# M5531 register map
File version: 1.0
Registers are 32-bit, read-write, reset 0x0 unless marked. A register's access mark holds for its fields unless they carry their own. Offsets are from the block's base; [hi:lo] are bit positions; 'fields as' and 'values as' point back to an identical list.

## GDMA (part 2 of 2) — GDMA Register Map
Base 0x04004000
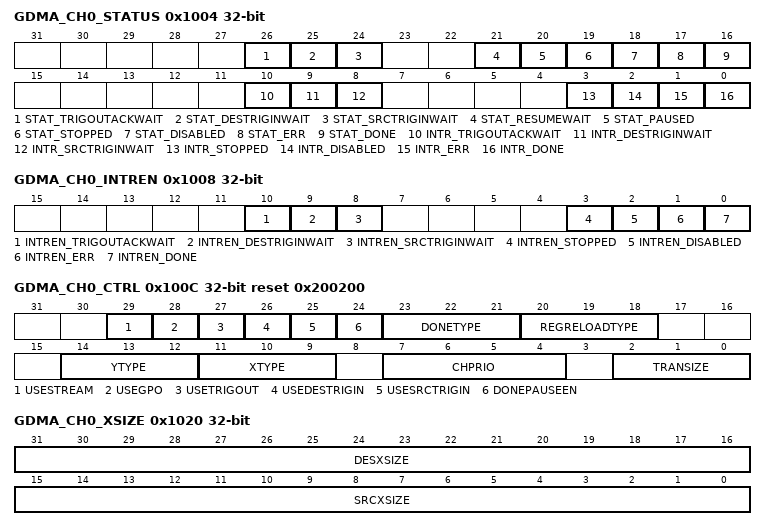
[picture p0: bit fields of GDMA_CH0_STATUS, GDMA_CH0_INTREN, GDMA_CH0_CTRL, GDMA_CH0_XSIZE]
0x1004 GDMA_CH0_STATUS — GDMA Channel Status Register
  [26] STAT_TRIGOUTACKWAIT — Channel is waiting for output Trigger Acknowledgement Status
    0=The output trigger acknowledgement is received either from HW or SW source; 1=DMA channel starts waiting for output trigger acknowledgement
  [25] STAT_DESTRIGINWAIT — Channel is waiting for Destination Trigger Status
    0=The destination trigger request is received either from HW or SW source; 1=DMA channel starts waiting for destination input trigger request
  [24] STAT_SRCTRIGINWAIT — Channel is waiting for Source Trigger Status
    0=The source trigger request is received either from HW or SW source; 1=DMA channel starts waiting for source input trigger request
  [21] STAT_RESUMEWAIT — Waiting for resume from software Flag. This flag indicates that the DMA channel successfully paused the operation of the command and needs SW acknowledgment to resume the operation.
    0=The RESUMECMD bit is set in the command register; 1=If STAT_PAUSED is asserted and the PAUSECMD bit set in the command register or when the STAT_DONE is asserted and the DONEPAUSEEN bit is set
  [20] STAT_PAUSED — Paused Status Flag
    0=When the request to pause is not asserted anymore and the command operation can continue; 1=The DMA channel successfully paused the operation of the command. The pause request can come from many internal or external sources
  [19] STAT_STOPPED — Stopped Status Flag
    0=Automatically cleared when the ENABLECMD is set; 1=The DMA channel successfully reached the stopped state. The stop request can come from many internal or external sources. Write '1' to this bit to clear it
  [18] STAT_DISABLED — Disabled Status Flag
    0=Automatically cleared when the ENABLECMD is set; 1=The DMA channel is successfully disabled using the DISABLECMD command. Write '1' to this bit to clear it
  [17] STAT_ERR — Error Status Flag. Write '1' to this bit to clear it. When cleared, it also clears the ERRINFO register.
    0=Automatically cleared when the ENABLECMD is set; 1=The DMA encounters an error during its operation. The details about the error event can be found in the ERRINFO register
  [16] STAT_DONE — Done Status Flag
    0=Automatically cleared when the ENABLECMD is set; 1=The DMA command reaches the state defined by the DONETYPE settings. When DONEPAUSEEN is set the DMA command operation is paused when this flag is asserted. Write '1' to this bit to clear it
  [10] INTR_TRIGOUTACKWAIT — Channel is waiting for output Trigger Acknowledgement Interrupt Flag
    0=Automatically cleared when STAT_TRIGOUTACKWAIT is cleared; 1=The INTREN_TRIGOUTACKWAIT is set and the STAT_TRIGOUTACKWAIT status flag is asserted
  [9] INTR_DESTRIGINWAIT — Channel is waiting for Destination Trigger Interrupt Flag
    0=Automatically cleared when STAT_DESTRIGINWAIT is cleared; 1=The INTREN_DESTRIGINWAIT is set and the STAT_DESTRIGINWAIT status flag is asserted
  [8] INTR_SRCTRIGINWAIT — Channel is waiting for Source Trigger Interrupt Flag
    0=Automatically cleared when STAT_SRCTRIGINWAIT is cleared; 1=The INTREN_SRCTRIGINWAIT is set and the STAT_SRCTRIGINWAIT status flag is asserted
  [3] INTR_STOPPED — Stopped Interrupt Flag
    0=Automatically cleared when STAT_STOPPED is cleared; 1=The INTREN_STOPPED is set and the STAT_STOPPED flag gets raised. 0
  [2] INTR_DISABLED — Disabled Interrupt Flag
    0=Automatically cleared when STAT_DISABLED is cleared; 1=The INTREN_DISABLED is set and the STAT_DISABLED flag gets raised
  [1] INTR_ERR — Error Interrupt Flag
    0=Automatically cleared when STAT_ERR is cleared; 1=The INTREN_ERR is set and the STAT_ERR status flag gets raised
  [0] INTR_DONE — Done Interrupt Flag
    0=Automatically cleared when STAT_DONE is cleared; 1=The INTREN_DONE is set and the STAT_DONE status flag gets raised
0x1008 GDMA_CH0_INTREN — GDMA Channel Interrupt Enable Register
  [10] INTREN_TRIGOUTACKWAIT — Channel is waiting for output Trigger Acknowledgement Interrupt Enable
    0=It prevents INTR_TRIGOUTACKWAIT to be asserted. Currently pending interrupts are not affected by clearing this bit; 1=Enables INTR_TRIGOUTACKWAIT to be set and raise an interrupt when STAT_TRIGOUTACKWAIT status flag is asserted
  [9] INTREN_DESTRIGINWAIT — Channel is waiting for destination Trigger Interrupt Enable
    0=It prevents INTR_DESTRIGINWAIT to be asserted. Currently pending interrupts are not affected by clearing this bit; 1=Enables INTR_DESTRIGINWAIT to be set and raise an interrupt when STAT_DESTRIGINWAIT status flag is asserted
  [8] INTREN_SRCTRIGINWAIT — Channel is waiting for Source Trigger Interrupt Enable
    0=It prevents INTR_SRCTRIGINWAIT to be asserted. Currently pending interrupts are not affected by clearing this bit; 1=Enables INTR_SRCTRIGINWAIT to be set and raise an interrupt when STAT_SRCTRIGINWAIT status flag is asserted
  [3] INTREN_STOPPED — Stopped Interrupt Enable
    0=It prevents INTR_STOPPED to be asserted. Currently pending interrupts are not affected by clearing this bit; 1=Enables INTR_STOPPED to be set and raise an interrupt when STAT_STOPPED status flag is asserted
  [2] INTREN_DISABLED — Disabled Interrupt Enable
    0=It prevents INTR_DISABLED to be asserted. Currently pending interrupts are not affected by clearing this bit; 1=Enables INTR_DISABLED to be set and raise an interrupt when STAT_DISABLED status flag is asserted
  [1] INTREN_ERR — Error Interrupt Enable
    0=It prevents INTR_ERR to be asserted. Currently pending interrupts are not affected by clearing this bit; 1=Enables INTR_ERROR to be set and raise an interrupt when the STAT_ERR status flag is asserted
  [0] INTREN_DONE — Done Interrupt Enable
    0=It prevents INTR_DONE to be asserted. Currently pending interrupts are not affected by clearing this bit; 1=Enables the INTR_DONE to be set and raise an interrupt when the STAT_DONE status flag is asserted
0x100C GDMA_CH0_CTRL reset 0x200200 — GDMA Channel Control Register
  [29] USESTREAM — Enable Stream Interface use for this command
    0=Disable; 1=Enable the field is RAZ/WI when the following condition is False: CH_STREAM_EN
  [28] USEGPO — Enable GPO use for this command (CH_GPO_EN * GPO_WIDTH) 0
    0=Disable; 1=Enable the field is RAZ/WI when the following condition is False:
  [27] USETRIGOUT — Enable Trigger Output use for this command
    0=Disable; 1=Enable
  [26] USEDESTRIGIN — Enable Destination Trigger Input use for this command
    0=Disable; 1=Enable
  [25] USESRCTRIGIN — Enable Source Trigger Input use for this command
    0=Disable; 1=Enable
  [24] DONEPAUSEEN — Done pause enable
    0=The assertion of the STAT_DONE does not pause the progress of the command and the next operation of the channel will be started immediately after the STAT_DONE flag is set; 1=The assertion of the STAT_DONE flag results in an automatic pause request for the current DMA operation. When the paused state is reached the STAT_RESUMEWAIT flag is also set
  [23:21] DONETYPE — Done type selection. This field defines when the STAT_DONE status flag is asserted during the command operation.
    0=STAT_DONE flag is not asserted for this command; 1=End of a command, before jumping to the next linked command. (default); 3=End of an autorestart cycle, before starting the next cycle
  [20:18] REGRELOADTYPE — Automatic register reload type. Defines how the DMA command reloads initial values at the end of a DMA command before autorestarting, ending or linking to a new DMA command: - 000: Reload Disabled. Note: When CLEARCMD is set, the reloaded registers will also be cleared
    1=Reload source and destination size registers only; 3=Reload source address only and all source and destination size registers; 5=Reload destination address only and all source and destination size registers; 7=Reload source and destination address and all source and destination size registers
  [14:12] YTYPE — Operation type for Y direction. Note: The field is RAZ/WI when the following condition is False: CH_EXT_FEAT_EN
    0='disable' - Only do 1D transfers. When HAS_2D is 0, meaning 2D capability is not supported in HW, the YTYPE is always '000'; 1='continue' - Copy 2D data in a continuous manner from source area to the destination area by using the YSIZE registers. The copy stops when the source runs out of data or the destination runs out of space. Not supported when HAS_2D is 0 in HW; 2='wrap' - Wrap the 2D source area within the destination 2D area by starting to copy data from the beginning of the first source line to the remaining space in the destination area. If the destination area is smaller than the source area then the behavior is UNPREDICTABLE. Not supported when HAS_WRAP or HAS_2D is 0 in HW; 3=Fill the remainder of the destination area with FILLVAL when the source area runs out of data. If the destination area is smaller than the source area then the behavior is UNPREDICTABLE. Not supported when HAS_WRAP or HAS_2D is 0 in HW
  [11:9] XTYPE — Operation type for X direction
    0='disable' - No data transfer will take place for this command. This mode can be used to create empty commands that wait for an event or set GPOs; 1='continue' - Copy data in a continuous manner from source to the destination; 2='wrap' - Wrap source data within a destination line when the end of the source line is reached. Read starts again from the beginning of the source line and copied to the remainder of the destination line; 3='fill' - Fill the remainder of the destination line with FILLVAL when the end of the source line is reached. If the DESXSIZE is smaller than SRCXSIZE then the behavior is UNPREDICTABLE. Not supported when HAS_WRAP is 0 in HW
  [7:4] CHPRIO — Channel Priority
    0=Lowest Priority; 15=Highest Priority
  [2:0] TRANSIZE — Transfer Entity Size. Note that DATA_WIDTH limits this field. Address will be aligned to TRANSIZE by the DMAC by ignoring the lower bits.
    0=Byte; 1=Halfworld; 2=Word; 3=Doubleword; 4=128-bits; 5=256-bits; 6=512-bits; 7=1024-bits
0x1010 GDMA_CH0_SRCADDR — GDMA Channel Source Address Register
  [31:0] SRCADDR — Source Address[31:0]
0x1018 GDMA_CH0_DESADDR — GDMA Channel Destination Address Register
  [31:0] DESADDR — Destination Address[31:0]
0x1020 GDMA_CH0_XSIZE — GDMA Channel X Dimension Size Register, Lower Bits [15:0]
  [31:16] DESXSIZE — Destination Number of Transfers in the X Dimension lower bits [15:0]. This register along with DESXSIZEHI defines the destination data block size of the DMA operation for or any 1D operation, and defines the X dimension of the 2D destination block for a 2D operation. HAS_WRAP or HAS_STREAM configuration needs to be set to allow writes to this register, otherwise it is read-only and writing to SRCXSIZE will also update the value of this register
  [15:0] SRCXSIZE — Source Number of Transfers in the X Dimension lower bits [15:0]. This register along with SRCXSIZEHI defines the source data block size of the DMA operation for any 1D operation, and defines the X dimension of the 2D source block for 2D operation.
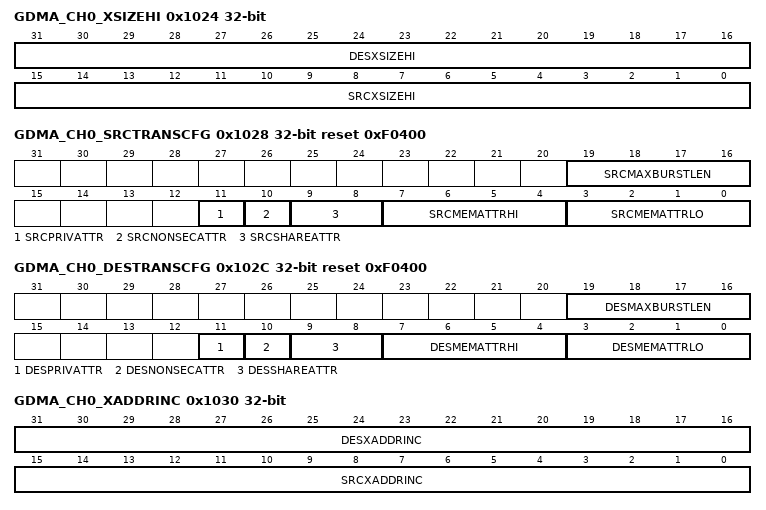
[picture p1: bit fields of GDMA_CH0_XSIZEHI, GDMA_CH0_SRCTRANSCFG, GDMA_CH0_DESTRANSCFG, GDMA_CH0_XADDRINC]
0x1024 GDMA_CH0_XSIZEHI — GDMA Channel X Dimension Size Register, High Bits [31:16]
  [31:16] DESXSIZEHI — Destination Number of Transfers in the X Dimension high bits [31:16]. This register along with DESXSIZE defines the destination data block size of the DMA operation for or any 1D operation, and defines the X dimension of the 2D destination block for a 2D operation. HAS_WRAP or HAS_STREAM configuration needs to be set to allow writes to this register, otherwise it is readonly and writing to SRCXSIZEHI will also update the value of this register.
  [15:0] SRCXSIZEHI — Source Number of Transfers in the X Dimension high bits [31:16]. This register along with SRCXSIZE defines the source data block size of the DMA operation for any 1D operation, and defines the X dimension of the 2D source block for 2D operation.
0x1028 GDMA_CH0_SRCTRANSCFG reset 0xF0400 — GDMA Channel Source Transfer Configuration Register
  [19:16] SRCMAXBURSTLEN — Source Max Burst Length. Hint for the DMA on what is the maximum allowed burst size it can use for read transfers. The maximum number of beats sent by the DMA for a read burst is equal to SRCMAXBURSTLEN + 1. Default value is 16 beats, which allows the DMA to set all burst sizes. Note: Limited by the DATA_BUFF_SIZE so larger settings may not always result in larger bursts.
  [11] SRCPRIVATTR — Source Transfer Privilege Attribute
    0=Unprivileged; 1=Privileged When a channel is unprivileged this bit is tied to 0
  [10] SRCNONSECATTR — Source Transfer Non-secure Attribute
    0=Secure; 1=Non-secure When a channel is Non-secure this bit is tied to 1
  [9:8] SRCSHAREATTR — SRCSHAREATTR Source Transfer Shareability Attribute
    0=Non-shareable; 2=Outer shareable; 3=Inner shareable
  [7:4] SRCMEMATTRHI — Source Transfer Memory Attribute field [7:4]
    0=Device memory; 1=Normal memory, Outer Write allocate, Outer Write-through transient; 2=Normal memory, Outer Read allocate, Outer Write-through transient; 3=Normal memory, Outer Read/Write allocate, Outer Write-through transient; 4=Normal memory, Outer non-cacheable; 5=Normal memory, Outer Write allocate, Outer Write-back transient; 6=Normal memory, Outer Read allocate, Outer Write-back transient; 7=Normal memory, Outer Read/Write allocate, Outer Write-back transient; 8=Normal memory, Outer Write-through non-transient; 9=Normal memory, Outer Write allocate, Outer Write-through non-transient; 10=Normal memory, Outer Read allocate, Outer Write-through non-transient; 11=Normal memory, Outer Read/Write allocate, Outer Write-through non-transient; 12=Normal memory, Outer Write-back non-transient; 13=Normal memory, Outer Write allocate, Outer Write-back non-transient; 14=Normal memory, Outer Read allocate, Outer Write-back non-transient; 15=Normal memory, Outer Read/Write allocate, Outer Write-back non-transient
  [3:0] SRCMEMATTRLO — Source Transfer Memory Attribute field [3:0]. When SRCMEMATTRHI is Device type (0000) then this field means:
    0=Device-nGnRnE. Reserved; 1=Normal memory, Inner Write allocate, Inner Write-through transient; 2=Normal memory, Inner Read allocate, Inner Write-through transient; 3=Normal memory, Inner Read/Write allocate, Inner Write-through transient; 4=Device-nGnRE. Normal memory, Inner non-cacheable; 5=Normal memory, Inner Write allocate, Inner Write-back transient; 6=Normal memory, Inner Read allocate, Inner Write-back transient; 7=Normal memory, Inner Read/Write allocate, Inner Write-back transient; 8=Device-nGRE. Normal memory, Inner Write-through non-transient; 9=Normal memory, Inner Write allocate, Inner Write-through non-transient; 10=Normal memory, Inner Read allocate, Inner Write-through non-transient; 11=Normal memory, Inner Read/Write allocate, Inner Write-through non-transient; 12=Device-GRE. Normal memory, Inner Write-back non-transient; 13=Normal memory, Inner Write allocate, Inner Write-back non-transient; 14=Normal memory, Inner Read allocate, Inner Write-back non-transient; 15=Normal memory, Inner Read/Write allocate, Inner Write-back non-transient
0x102C GDMA_CH0_DESTRANSCFG reset 0xF0400 — GDMA Channel Destination Transfer Configuration Register
  [19:16] DESMAXBURSTLEN — Destination Max Burst Length. Hint for the DMA on what is the maximum allowed burst size it can use for write transfers. The maximum number of beats sent by the DMA for a write burst is equal to DESMAXBURSTLEN + 1. Default value is 16 beats, which allows the DMA to set all burst sizes. Note: Limited by the DATA_BUFF_SIZE so larger settings may not always result in larger bursts.
  [11] DESPRIVATTR — Destination Transfer Privilege Attribute
    values as GDMA_CH0_SRCTRANSCFG.SRCPRIVATTR
  [10] DESNONSECATTR — Destination Transfer Non-secure Attribute
    values as GDMA_CH0_SRCTRANSCFG.SRCNONSECATTR
  [9:8] DESSHAREATTR — Destination Transfer Shareability Attribute
    0=Non-shareable; 2=Outer shareable; 3=Inner shareable
  [7:4] DESMEMATTRHI — Destination Transfer Memory Attribute field [7:4]
    values as GDMA_CH0_SRCTRANSCFG.SRCMEMATTRHI
  [3:0] DESMEMATTRLO — Destination Transfer Memory Attribute field [3:0]. When DESMEMATTRHI is Device type (0000) then this field means:
    values as GDMA_CH0_SRCTRANSCFG.SRCMEMATTRLO
0x1030 GDMA_CH0_XADDRINC — GDMA Channel X Dimension Address Increment Register
  [31:16] DESXADDRINC — Destination X dimension Address Increment
  [15:0] SRCXADDRINC — Source X dimension Address Increment
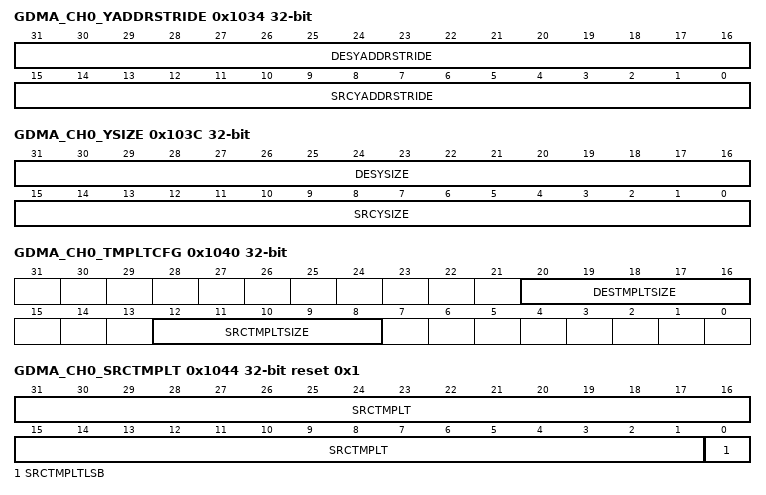
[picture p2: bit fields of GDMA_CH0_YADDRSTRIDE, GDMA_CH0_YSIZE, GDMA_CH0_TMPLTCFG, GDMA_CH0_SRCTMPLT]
0x1034 GDMA_CH0_YADDRSTRIDE — GDMA Channel Y Dimension Address Stride Register
  [31:16] DESYADDRSTRIDE — Destination Address Stride between lines
  [15:0] SRCYADDRSTRIDE — Source Address Stride between lines
0x1038 GDMA_CH0_FILLVAL — GDMA Channel Fill Pattern Value Register
  [31:0] FILLVAL — Fill pattern value. When XTYPE or YTYPE is set to fill mode, then this register value is used on the write data bus when the command starts to fill the memory area. The TRANSIZE defines the width of the FILLVAL used for the command. For byte transfers the FILLVAL[7:0] is used, other bits are ignored. For halfword transfers the FILLVAL[15:0] is used, other bits are ignored. For 64-bit and wider transfers the FILLVAL[31:0] pattern is repeated on the full width of the data bus. Not present when HAS_WRAP is 0. The field is RAZ/WI when the following condition is False: CH_EXT_FEAT_EN
0x103C GDMA_CH0_YSIZE — GDMA Channel Y Dimensions Size Register
  [31:16] DESYSIZE — Destination Y dimension or number of lines. Not present when HAS_2D is 0. HAS_WRAP or HAS_STREAM configuration needs to be set to allow writes to this register, otherwise it is read-only. The field is RAZ/WI when the following condition is False: CH_EXT_FEAT_EN
  [15:0] SRCYSIZE — Source Y dimension or number of lines. Not present when HAS_2D is 0. The field is RAZ/WI when the following condition is False: CH_EXT_FEAT_EN
0x1040 GDMA_CH0_TMPLTCFG — GDMA Channel Template Configuration Register
  [20:16] DESTMPLTSIZE — Destination Template Size in number of transfers plus one
    0=Destination template is disabled
  [12:8] SRCTMPLTSIZE — Source Template Size in number of transfers plus one
    0=Source template is disabled
0x1044 GDMA_CH0_SRCTMPLT reset 0x1 — GDMA Channel 0 Source Template Pattern Register
  [31:1] SRCTMPLT — Source Packing Template. Bit[0] is read only and always set to 1 as template patterns can only start from the base address of the transfer. Not present when HAS_TMPLT is 0. The field is RAZ/WI when the following condition is False: CH_EXT_FEAT_EN
  [0] SRCTMPLTLSB — Source Packing Template Least Significant Bit. This bit of the template is read only and always set to 1 as template patterns can only start from the base address of the transfer. Not present when HAS_TMPLT is 0. The field is RAZ/WI when the following condition is False: CH_EXT_FEAT_EN
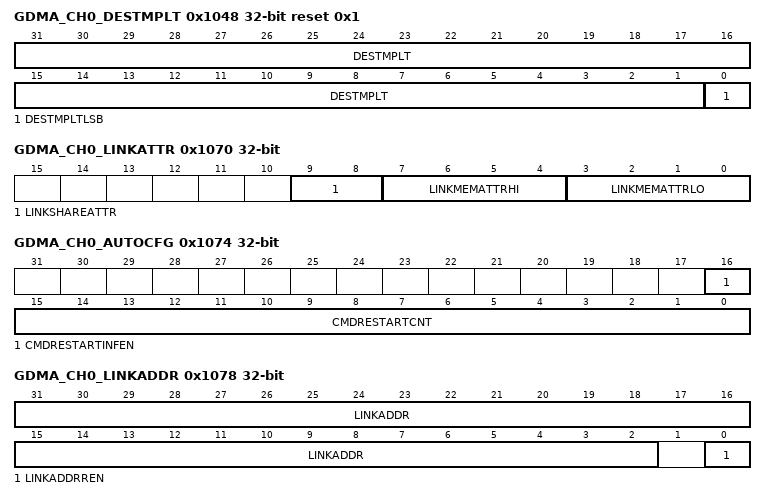
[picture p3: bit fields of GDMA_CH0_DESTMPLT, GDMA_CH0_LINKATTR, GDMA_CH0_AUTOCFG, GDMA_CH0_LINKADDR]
0x1048 GDMA_CH0_DESTMPLT reset 0x1 — GDMA Channel 0 Destination Template Pattern Register
  [31:1] DESTMPLT — Destination Packing Template. Bit[0] is read only and always set to 1 as template patterns can only start from the base address of the transfer. Not present when HAS_TMPLT is 0. The field is RAZ/WI when the following condition is False: CH_EXT_FEAT_EN
  [0] DESTMPLTLSB — Destination Packing Template Least Significant Bit. This bit of the template is read only and always set to 1 as template patterns can only start from the base address of the transfer. Not present when HAS_TMPLT is 0. The field is RAZ/WI when the following condition is False: CH_EXT_FEAT_EN
0x1070 GDMA_CH0_LINKATTR — GDMA Channel Link Address Memory Attributes Register
  [9:8] LINKSHAREATTR — Link Address Transfer Shareability Attribute
    0=Non-shareable; 2=Outer shareable; 3=Inner shareable
  [7:4] LINKMEMATTRHI — Link Address Read Transfer Memory Attribute field [7:4]
    0=Device memory; 1=Normal memory, Outer Write allocate, Outer Write-through transient; 2=Normal memory, Outer Read allocate, Outer Write-through transient; 3=Normal memory, Outer Read/Write allocate, Outer Write-through transient; 4=Normal memory, Outer non-cacheable; 5=Normal memory, Outer Write allocate, Outer Write-back transient; 6=Normal memory, Outer Read allocate, Outer Write-back transient; 7=Normal memory, Outer Read/Write allocate, Outer Write-back transient; 8=Normal memory, Outer Write-through non-transient; 9=Normal memory, Outer Write allocate, Outer Write-through non-transient; 10=Normal memory, Outer Read allocate, Outer Write-through non-transient; 11=Normal memory, Outer Read/Write allocate, Outer Write-through non-transient; 12=Normal memory, Outer Write-back non-transient; 13=Normal memory, Outer Write allocate, Outer Write-back non-transient; 14=Normal memory, Outer Read allocate, Outer Write-back non-transient; 15=Normal memory, Outer Read/Write allocate, Outer Write-back non-transien
  [3:0] LINKMEMATTRLO — Link Address Read Transfer Memory Attribute field [3:0]. When LINKMEMATTRHI is Device type (0000) then this field means:
    values as GDMA_CH0_SRCTRANSCFG.SRCMEMATTRLO
0x1074 GDMA_CH0_AUTOCFG — GDMA Channel Automatic Command Restart Configuration Register
  [16] CMDRESTARTINFEN — Enable Infinite Automatic Command Restart. When set, CMDRESTARTCNT is ignored and the command is always restarted after it is completed, including output triggering if enabled and autoreloading the registers but it will not perform a link to the next command. This means that the infinite loop of automatic restarts can only be broken by DISABLECMD or STOPCMD. When CMDRESTARTINFEN is set to '0', then the autorestarting of a command depends on CMDRESTARTCNT and when that counter is set to 0 the autorestarting is finished. In this case the next linked command is read or the command is complete
  [15:0] CMDRESTARTCNT — Automatic Command Restart Counter
0x1078 GDMA_CH0_LINKADDR — GDMA Channel Link Address Register
  [31:2] LINKADDR — Link Address Pointer[31:2]. The DMAC fetches the next command from this address if LINKADDREN is set. Note: Commands are fetched with the security and privilege attribute of the channel and cannot be adjusted for the command link reads.
  [0] LINKADDRREN — Enable Link Address. Note: the linked command fetched by the DMAC needs to clear this field to mark the end of the command chain. Otherwise it may result in an infinite loop of the same command
    0=The DMAC will return to idle at the end of the current command; 1=The DMAC fetches the next command defined by LINKADDR
0x1088 GDMA_CH0_WRKREGPTR — GDMA Channel Working Register Pointer Register
  [3:0] WRKREGPTR — Internal Working Register Pointer. These pointer refers to the following: Note: When the selected register is not supported by the DMA then it is read as 0 in the CH_WRKREGVAL register. For 1D modes the INITIAL and LINEINITIAL registers contain the same values.
    1=SRCADDR_INITIAL; 2=SRCADDRHI_INITIAL; 3=DESADDR_INITIAL; 4=DESADDRHI_INITIAL; 5=SRCXSIZEHI_INITIAL, SRCXSIZE_INITIAL; 6=DESXSIZEHI_INITIAL, DESXSIZE_INITIAL; 7=SRCADDR_LINEINITIAL; 8=SRCADDRHI_LINEINITIAL; 9=DESADDR_LINEINITIAL; 10=DESADDRHI_LINEINITIAL; 11=SRCYSIZE_INITIAL (HAS_2D only); 12=DESYSIZE_INITIAL (HAS_2D only)
0x108C GDMA_CH0_WRKREGVAL ro — GDMA Channel - Working Register Value Register
  [31:0] WRKREGVAL — Internal Working Register Values. WRKREGPTR points to the register that is visible here. The values are only guaranteed to be stable for the current command when STAT_PAUSED is asserted, otherwise they depend on the current status of the channel which makes them UNPREDICTABLE.
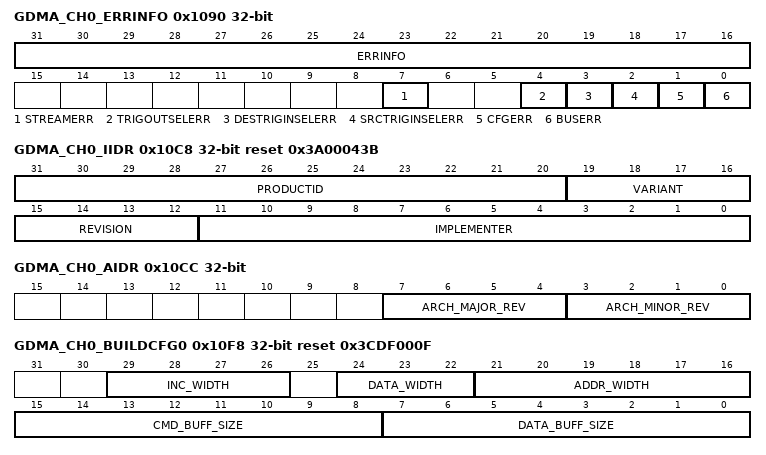
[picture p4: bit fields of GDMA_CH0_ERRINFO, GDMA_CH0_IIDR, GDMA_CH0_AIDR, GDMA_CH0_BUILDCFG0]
0x1090 GDMA_CH0_ERRINFO ro — GDMA Channel Error Information Register
  [31:16] ERRINFO — Error information Register. Additional information for the error that is encountered by the DMA. The meaning of the bits are detailed in the Error Handling section.
  [7] STREAMERR — Stream Interface Error Flag. Set when the stream interface encountered an error. The field is RAZ/WI when the following condition is False: CH_STREAM_EN
  [4] TRIGOUTSELERR — Trigger Output Selection Error Flag. Set when the command selects a trigger output that is not allowed for this channel
  [3] DESTRIGINSELERR — Destination Trigger Input Selection Error Flag. Set when the command selects a destination trigger input that is not allowed for this channel.
  [2] SRCTRIGINSELERR — Source Trigger Input Selection Error Flag. Set when the command selects a source trigger input that is not allowed for this channel.
  [1] CFGERR — Configuration Error Flag. Set when the DMA command is enabled or a linked command is read but it is configured in a mode that is not supported by the implementation.
  [0] BUSERR — Bus Error Flag. Set when the DMA encounters a bus error during data or command read transfers.
0x10C8 GDMA_CH0_IIDR ro reset 0x3A00043B — GDMA Channel Implementation Identification Register
  [31:20] PRODUCTID — Product ID. Indicates the product ID
  [19:16] VARIANT — Variant ID. Indicates the major revision, or variant, of the product rxpy identifier
  [15:12] REVISION — Minor Revision. Indicates the minor revision of the product rxpy identifier
  [11:0] IMPLEMENTER — Implementer Code. Contains the JEP106 code of the company that implemented the IP: - [11:8]: JEP106 continuation code of implementer. - [7]: Always 0. - [6:0]: JEP106 identity code of implementer. For Arm this field reads as 0x43B.
0x10CC GDMA_CH0_AIDR ro — GDMA Channel Architecture Identification Register
  [7:4] ARCH_MAJOR_REV — Architecture Major Revision
  [3:0] ARCH_MINOR_REV — Architecture Minor Revision
0x10E8 GDMA_CH0_ISSUECAP reset 0x7 — GDMA Used for setting issuing capability threshold
  [2:0] ISSUECAP — ISSUECAP. ISSUECAP can be used by software to place a constraint on allowed issuing capability in both read and write direction.
0x10F8 GDMA_CH0_BUILDCFG0 ro reset 0x3CDF000F — GDMA Channel Build Configuration and Capability Register 0
  [29:26] INC_WIDTH — Width of the increment
  [24:22] DATA_WIDTH
    0=8-bit; 1=16-bit; 2=32-bit; 3=64-bit; 4=128-bit; 5=256-bit; 6=512-bit; 7=1024-bit
  [21:16] ADDR_WIDTH — Address Width
  [15:8] CMD_BUFF_SIZE — Command Buffer Size
  [7:0] DATA_BUFF_SIZE — Data Buffer Size
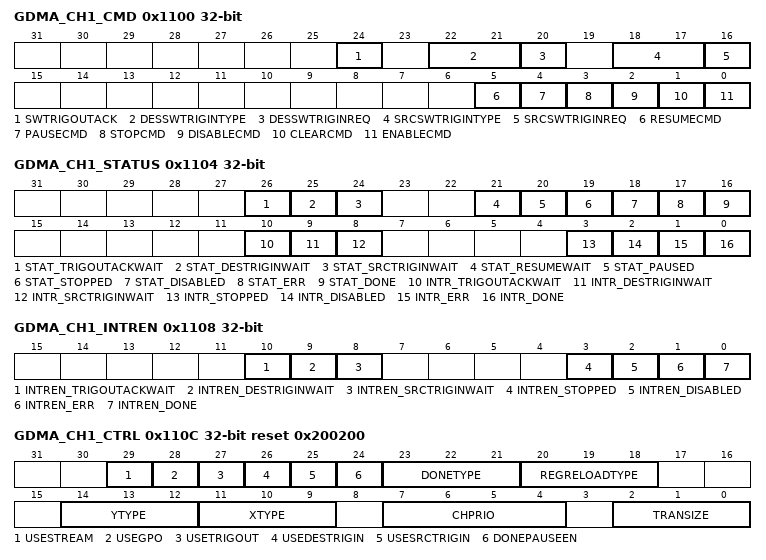
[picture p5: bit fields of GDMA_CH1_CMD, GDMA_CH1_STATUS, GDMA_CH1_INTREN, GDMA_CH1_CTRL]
0x1100 GDMA_CH1_CMD — GDMA Channel Command Register
  [24] SWTRIGOUTACK — Software Generated Trigger Output Acknowledge. Write '1' to acknowledge a Trigger Output request from the DMA. Once set to '1', this will remain high until the DMA Trigger Output is raised (either on the trigger output signal or as an interrupt) and the acknowledge is accepted. Note: When the channel is not enabled, write to this register is ignored.
  [22:21] DESSWTRIGINTYPE — Software Generated Destination Trigger Input Request Type. Selects the trigger request type for the destination trigger input when the SW triggers the DESSWTRIGINREQ bit. Note: This field cannot be changed while the DESSWTRIGINREQ bit is set. The field is RAZ/WI when the following condition is False: (1) (NUM_TRIGGER_IN 0)
    0=Single request; 1=Last single request; 2=Block request; 3=Last block request
  [20] DESSWTRIGINREQ — Software Generated Destination Trigger Input Request. Write to '1' to create a SW trigger request to the DMA with the specified type in the DESSWTRIGINTYPE register. Once set to '1', this will remain high until the DMA is accepted the trigger and will return this to '0'. It will also be cleared automatically if the current command is completed without expecting another trigger event. Note: When the channel is not enabled, write to this register is ignored
  [18:17] SRCSWTRIGINTYPE — Software Generated Source Trigger Input Request Type. Selects the trigger request type for the source trigger input when the SW triggers the SRCSWTRIGINREQ bit. Note: This field cannot be changed while the SRCSWTRIGINREQ bit is set. The field is RAZ/WI when the following condition is False: (1) (NUM_TRIGGER_IN 0)
    values as DESSWTRIGINTYPE
  [16] SRCSWTRIGINREQ — Software Generated Source Trigger Input Request. Write to '1' to create a SW trigger request to the DMA with the specified type in the SRCSWTRIGINTYPE register. Once set to '1', this will remain high until the DMA accepted the trigger and will return this to '0'. It will also be cleared automatically if the current command is completed without expecting another trigger event. Note: When the channel is not enabled, write to this register is ignored.
  [5] RESUMECMD — Resume Current DMA Operation. Writing this bit to '1' means that the DMAC can continue the operation of a paused channel. Can be set to '1' when the PAUSECMD or a STAT_DONE assertion with DONEPAUSEEN set HIGH results in pausing the current DMA channel operation indicated by the STAT_PAUSED and STAT_RESUMEWAIT bits. Otherwise, writes to this bit are ignored.
  [4] PAUSECMD — Pause Current DMA Operation. Once set to '1' the status cannot change until the DMA operation reached the paused state indicated by the STAT_PAUSED and STAT_RESUMEWAIT bits. The bit can be set by SW by writing it to '1', the current active DMA operation will be paused as soon as possible, but the ENABLECMD bit will remain HIGH to show that the operation is still active. Cleared automatically when STAT_RESUMEWAIT is set and the RESUMECMD bit is written to '1', meaning that the SW continues the operation of the channel. Note: each DMA channel can have other sources of a pause request and this field will not reflect the state of the other sources. When set at the same time as ENABLECMD or when the channel is not enabled then write to this register is ignored.
  [3] STOPCMD — Stop Current DMA Operation. Once set to '1', his will remain high until the DMA channel is stopped cleanly. Then this will return to '0' and ENABLECMD is also cleared. When set at the same time as ENABLECMD or when the channel is not enabled then write to this register is ignored. Note that each DMA channel can have other sources of a stop request and this field will not reflect the state of the other sources.
  [2] DISABLECMD — Disable DMA Operation at the end of the current DMA command operation. Once set to '1', this field will stay high and the current DMA command will be allowed to complete, but the DMA will not fetch the next linked command or will it auto-restart the DMA command even if they are set. Once the DMA has stopped, it will return to '0' and ENABLECMD is also cleared. When set at the same time as ENABLECMD or when the channel is not enabled then write to this register is ignored
  [1] CLEARCMD — DMA Clear command. When set to '1', it will remain high until all DMA channel registers and any internal queues and buffers are cleared, before returning to '0'. When set at the same time as ENABLECMD or while the DMA channel is already enabled, the clear will only occur after any ongoing DMA operation is either completed, stopped or disabled and the ENABLECMD bit is deasserted by the DMA.
  [0] ENABLECMD — Channel Enable. When set to '1', enables the channel to run its programmed task. When set to '1', it cannot be set back to zero, and this field will automatically clear to zero when a DMA process is completed. To force the DMA to stop prematurely, you must use CH_CMD.STOPCMD instead
0x1104 GDMA_CH1_STATUS — GDMA Channel Status Register
  fields as GDMA_CH0_STATUS
0x1108 GDMA_CH1_INTREN — GDMA Channel Interrupt Enable Register
  fields as GDMA_CH0_INTREN
0x110C GDMA_CH1_CTRL reset 0x200200 — GDMA Channel Control Register
  fields as GDMA_CH0_CTRL
0x1110 GDMA_CH1_SRCADDR — GDMA Channel Source Address Register
  [31:0] SRCADDR — Source Address[31:0]
0x1118 GDMA_CH1_DESADDR — GDMA Channel Destination Address Register
  [31:0] DESADDR — Destination Address[31:0]
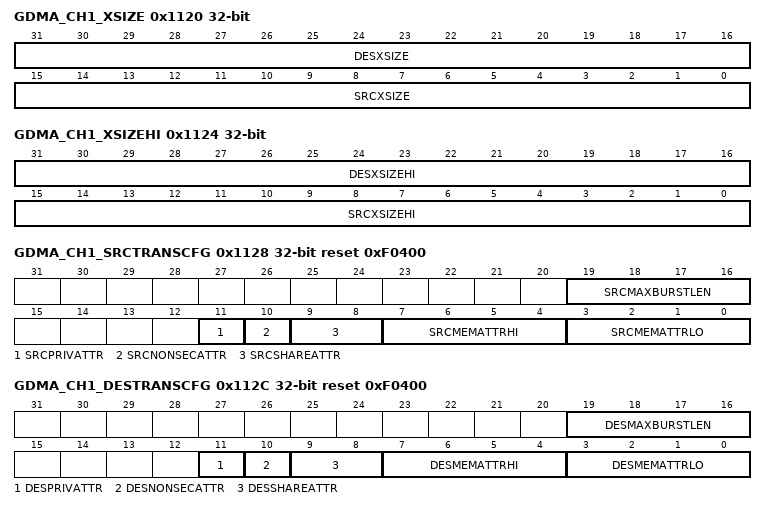
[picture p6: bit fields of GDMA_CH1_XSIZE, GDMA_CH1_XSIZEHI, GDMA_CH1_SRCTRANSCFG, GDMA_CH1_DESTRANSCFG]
0x1120 GDMA_CH1_XSIZE — GDMA Channel X Dimension Size Register, Lower Bits [15:0]
  fields as GDMA_CH0_XSIZE
0x1124 GDMA_CH1_XSIZEHI — GDMA Channel X Dimension Size Register, High Bits [31:16]
  fields as GDMA_CH0_XSIZEHI
0x1128 GDMA_CH1_SRCTRANSCFG reset 0xF0400 — GDMA Channel Source Transfer Configuration Register
  fields as GDMA_CH0_SRCTRANSCFG
0x112C GDMA_CH1_DESTRANSCFG reset 0xF0400 — GDMA Channel Destination Transfer Configuration Register
  fields as GDMA_CH0_DESTRANSCFG
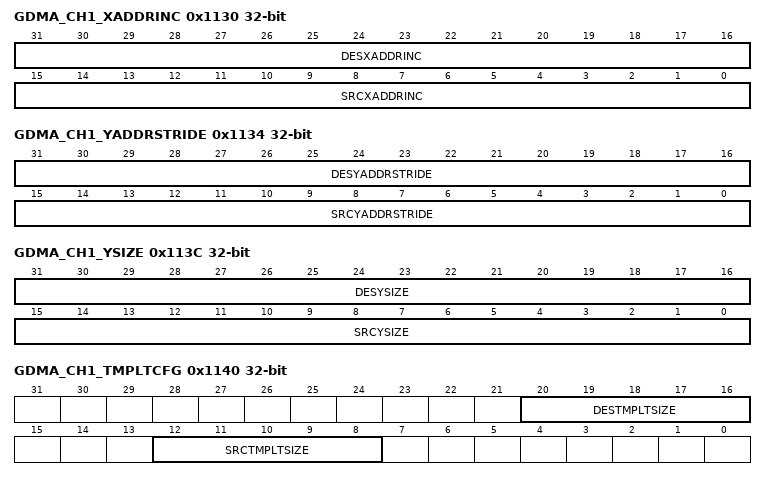
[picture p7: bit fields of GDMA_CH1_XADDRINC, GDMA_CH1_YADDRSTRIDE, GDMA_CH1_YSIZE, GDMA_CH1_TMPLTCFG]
0x1130 GDMA_CH1_XADDRINC — GDMA Channel X Dimension Address Increment Register
  fields as GDMA_CH0_XADDRINC
0x1134 GDMA_CH1_YADDRSTRIDE — GDMA Channel Y Dimension Address Stride Register
  fields as GDMA_CH0_YADDRSTRIDE
0x1138 GDMA_CH1_FILLVAL — GDMA Channel Fill Pattern Value Register
  fields as GDMA_CH0_FILLVAL
0x113C GDMA_CH1_YSIZE — GDMA Channel Y Dimensions Size Register
  fields as GDMA_CH0_YSIZE
0x1140 GDMA_CH1_TMPLTCFG — GDMA Channel Template Configuration Register
  fields as GDMA_CH0_TMPLTCFG
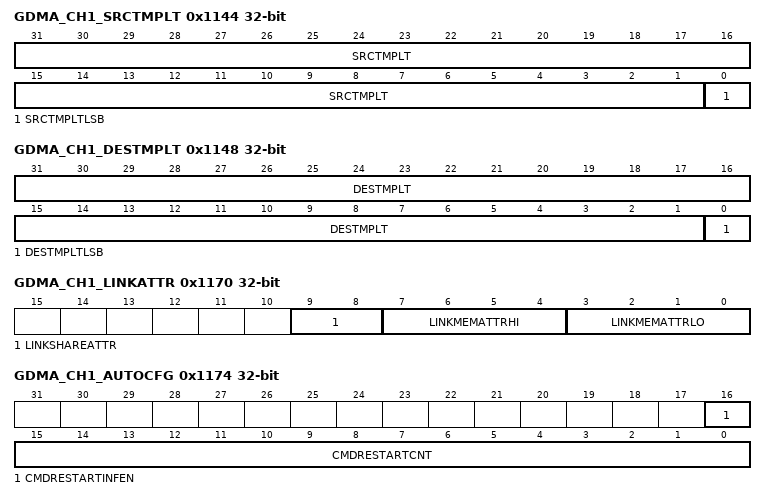
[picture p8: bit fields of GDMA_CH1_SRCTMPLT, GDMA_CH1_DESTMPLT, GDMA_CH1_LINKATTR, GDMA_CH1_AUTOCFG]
0x1144 GDMA_CH1_SRCTMPLT — GDMA Channel 1 Source Template Pattern Register
  fields as GDMA_CH0_SRCTMPLT
0x1148 GDMA_CH1_DESTMPLT — GDMA Channel 1 Destination Template Pattern Register
  fields as GDMA_CH0_DESTMPLT
0x1170 GDMA_CH1_LINKATTR — GDMA Channel Link Address Memory Attributes Register
  fields as GDMA_CH0_LINKATTR
0x1174 GDMA_CH1_AUTOCFG — GDMA Channel Automatic Command Restart Configuration Register
  fields as GDMA_CH0_AUTOCFG
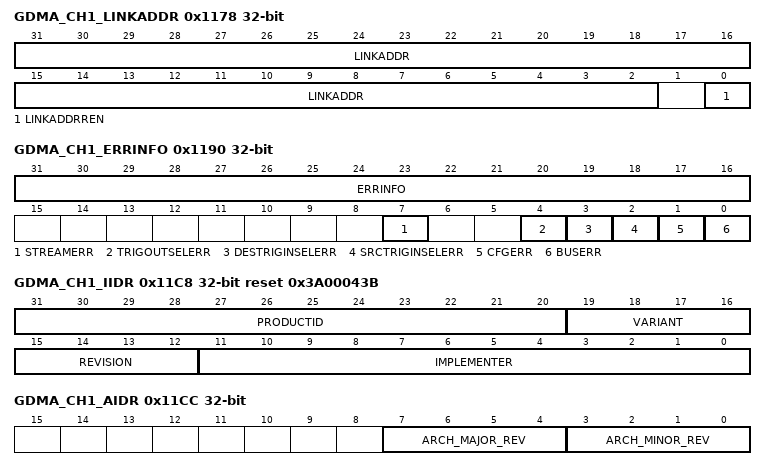
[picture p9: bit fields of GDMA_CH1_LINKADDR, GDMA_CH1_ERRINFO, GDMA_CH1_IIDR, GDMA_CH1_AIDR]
0x1178 GDMA_CH1_LINKADDR — GDMA Channel Link Address Register
  fields as GDMA_CH0_LINKADDR
0x1188 GDMA_CH1_WRKREGPTR — GDMA Channel Working Register Pointer Register
  fields as GDMA_CH0_WRKREGPTR
0x118C GDMA_CH1_WRKREGVAL ro — GDMA Channel - Working Register Value Register
  fields as GDMA_CH0_WRKREGVAL
0x1190 GDMA_CH1_ERRINFO ro — GDMA Channel Error Information Register
  fields as GDMA_CH0_ERRINFO
0x11C8 GDMA_CH1_IIDR ro reset 0x3A00043B — GDMA Channel Implementation Identification Register
  fields as GDMA_CH0_IIDR
0x11CC GDMA_CH1_AIDR ro — GDMA Channel Architecture Identification Register
  fields as GDMA_CH0_AIDR
0x11E8 GDMA_CH1_ISSUECAP reset 0x7 — GDMA Used for setting issuing capability threshold
  fields as GDMA_CH0_ISSUECAP
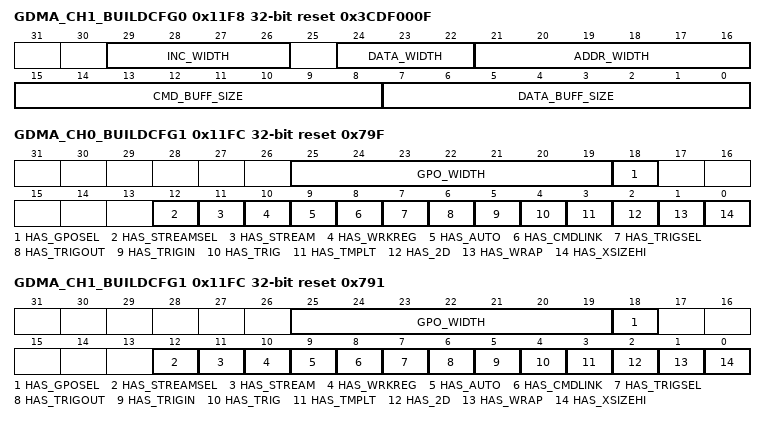
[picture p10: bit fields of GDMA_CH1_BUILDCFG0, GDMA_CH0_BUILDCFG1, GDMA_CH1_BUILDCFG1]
0x11F8 GDMA_CH1_BUILDCFG0 ro reset 0x3CDF000F — GDMA Channel Build Configuration and Capability Register 0
  fields as GDMA_CH0_BUILDCFG0
0x11FC GDMA_CH0_BUILDCFG1 ro reset 0x79F — GDMA Channel Build Configuration and Capability Register 1 (CH0)
  [25:19] GPO_WIDTH — General Purpose Output Width 0 to 64. The field is RAZ/WI when the following condition is False: (CH_GPO_EN * GPO_WIDTH) 0
  [18] HAS_GPOSEL — Has shared GPO ports between channels.
  [12] HAS_STREAMSEL — Has selectable stream interfaces.
  [11] HAS_STREAM — Has stream interface support.
  [10] HAS_WRKREG — Has internal register view capability
  [9] HAS_AUTO — Has automatic reload and restart capability.
  [8] HAS_CMDLINK — Has command link list capability.
  [7] HAS_TRIGSEL — Has selectable triggers.
  [6] HAS_TRIGOUT — Has hardware trigger output port.
  [5] HAS_TRIGIN — Has hardware trigger input ports.
  [4] HAS_TRIG — Has trigger capability
  [3] HAS_TMPLT — Has template based pack and unpack capability.
  [2] HAS_2D — Has 2D capability
  [1] HAS_WRAP — Has wrap capability
  [0] HAS_XSIZEHI — Has 32-bit XSIZE counters
0x11FC GDMA_CH1_BUILDCFG1 ro reset 0x791 (alternate view of GDMA_CH0_BUILDCFG1) — GDMA Channel Build Configuration and Capability Register 1 (CH1)
  fields as GDMA_CH0_BUILDCFG1
